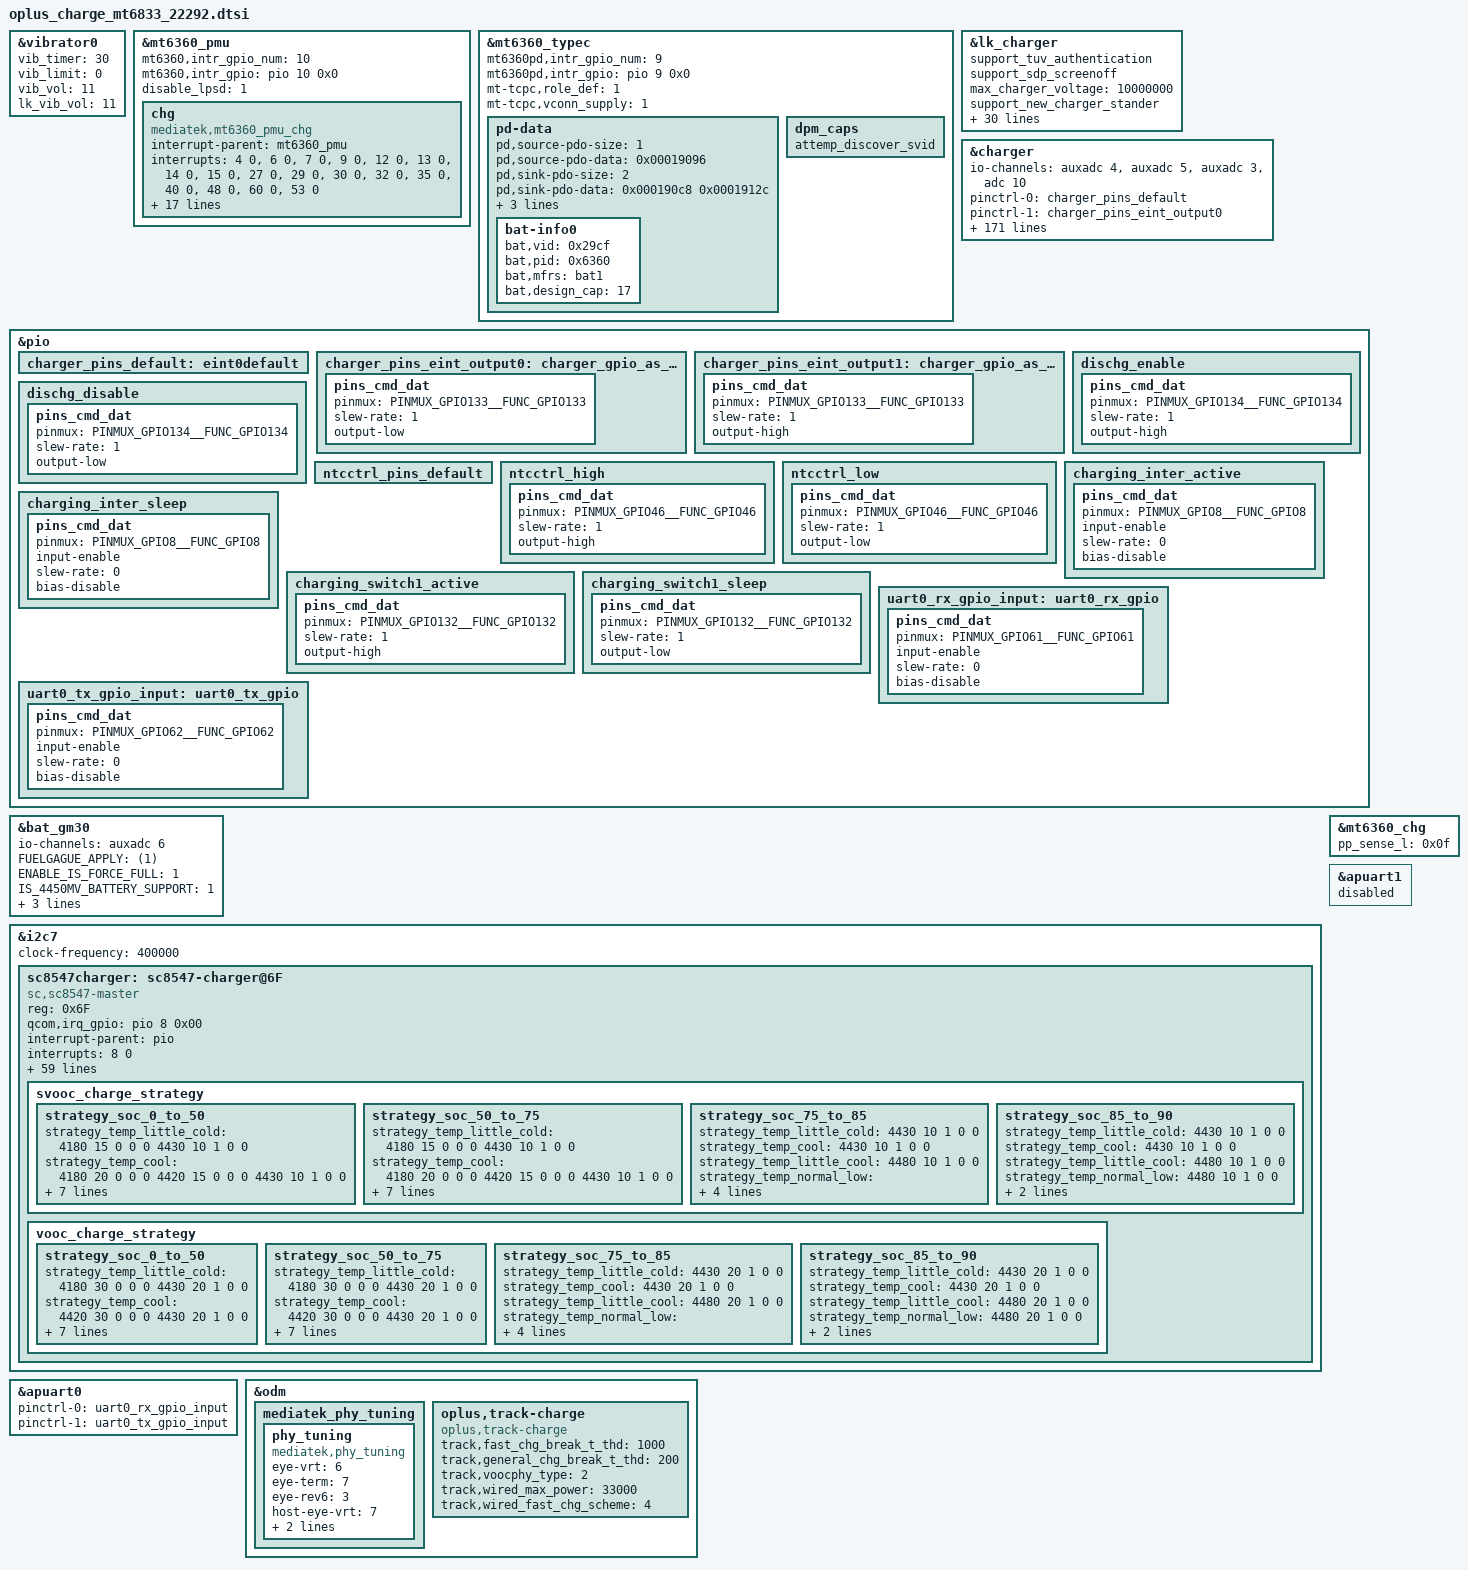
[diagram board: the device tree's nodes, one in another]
// SPDX-License-Identifier: GPL-2.0-only
/*
* Copyright (C) 2020-2021 Oplus. All rights reserved.
*/

//#ifdef OPLUS_FEATURE_CHG_BASIC
/*
 *
 * CPU:				--> MT6877
 * GPIO:
 * PERIEN_CHG_ENB		--> GPIO142
 * MT6360_SCL			--> GPIO132(SCL5)
 * MT6360_SDA			--> GPIO133(SDA5)
 * EINT_SUBPMIC_IRQB		--> GPIO4
 * EINT_SUBPMIC_PD_IRQB		--> GPIO5
 *
 * GAUGE_SCL			--> GPIO134(SCL7)
 * GAUGE_SDA			--> GPIO135(SDA7)
 * AP_CLK			--> GPIO180
 * AP_DATA			--> GPIO181
 * SW_CTRL			--> GPIO24
 * USB_ON			--> GPIO25
 * MCU_EN			--> GPIO33
 * ASIC_ID			--> GPIO34
 * ASIC_INT			--> GPIO9
 * SHIP_MODE_ON			--> GPIO108
 * UTXD0			--> GPIO178
 * URXD0			--> GPIO179
 *
 * USB_ACC_INT			--> GPIO6
 * VBUS_SHORT			--> GPIO167(VIO28)
 *
 * CHG_INT			--> GPIO10
 * CP_ID			--> GPIO31
 *
 * AUXADC:
 * 0				--> AUX_IN0_NTC_AP
 * 1				--> AUX_IN1_NTC_PA1
 * 2				--> AUX_IN2_NTC_PA2
 * 3				--> CAM_FLASH_THER
 * 4				--> USB_TEM_ADC_1
 * 5				--> USB_TEM_ADC_2
 * 6				--> CHG_MOS_THERM
 * 7				--> BATCON_TEM_ADC_MCU
 * 8				--> USBCON_TEM_ADC_MCU
 *******************************************
 * main pmic:			--> MT6365
 * charge pmic:			--> MT6360
 * charge ic:			--> MT6360
 * CP:				--> SC8547
 * GAUGE:			--> MT6365
 * asic ic:
 * PD				--> SY6610
 * HZ				--> RT5125
 * PU				--> RK826
 */

&vibrator0 {
	vib_timer = <30>;
	vib_limit = <0>;
	vib_vol= <11>;
	lk_vib_vol  = <11>;
	status = "okay";
};

&mt6360_pmu {
	mt6360,intr_gpio_num = <10>; /* direct defined GPIO num */
	mt6360,intr_gpio = <&pio 10 0x0>;
	disable_lpsd = <1>;

	chg {
		compatible = "mediatek,mt6360_pmu_chg";
		interrupt-parent = <&mt6360_pmu>;
		interrupts = <4 0>, <6 0>, <7 0>, <9 0>,
				<12 0>, <13 0>, <14 0>, <15 0>,
				<27 0>, <29 0>, <30 0>, <32 0>,
				<35 0>, <40 0>, <48 0>, <60 0>,
				<53 0>;
		interrupt-names = "chg_treg_evt", "chg_mivr_evt",
				"pwr_rdy_evt", "chg_batsysuv_evt",
				"chg_vsysuv_evt", "chg_vsysov_evt",
				"chg_vbatov_evt", "chg_vbusov_evt",
				"chg_tmri", "chg_adpbadi",
				"chg_rvpi",  "chg_aiccmeasl",
				"wdtmri", "pumpx_donei",
				"attachi", "chrdet_ext_evt",
				"hvdcp_det";
		io-channels = <&adc 0>, <&adc 1>, <&adc 3>, <&adc 4>,
				<&adc 5>, <&adc 6>, <&adc 8>, <&adc 10>;
		io-channel-names = "USBID", "VBUSDIV5", "VSYS", "VBAT",
				"IBUS", "IBAT", "TEMP_JC", "TS";
		chg_name = "primary_chg";
		ichg = <2000000>;               /* uA */
		aicr = <500000>;                /* uA */
		mivr = <4400000>;               /* uV */
		cv = <4350000>;                 /* uA */
		ieoc = <150000>;                /* uA */
		safety_timer = <20>;            /* hour */
		ircmp_resistor = <25000>;       /* uohm */
		ircmp_vclamp = <32000>;         /* uV */
		en_te = <1>;
		en_wdt = <1>;
		aicc_once = <1>;
		post_aicc = <1>;
		batoc_notify = <0>;
		support_hvdcp;
	};
};

&mt6360_typec {
	mt6360pd,intr_gpio_num = <9>; /* direct defined GPIO num */
	mt6360pd,intr_gpio = <&pio 9 0x0>;
	mt-tcpc,role_def = <1>;  /* 0: Unknown, 1: SNK only, 2: SRC only, 3: DRP, 4: Try.SRC, 5: Try.SNK */
	mt-tcpc,vconn_supply  = <1>; /* 0: Never, 1: Always, 2: EMarkOnly, 3: StartOnly */
	pd-data {
		pd,source-pdo-size = <1>;
		pd,source-pdo-data = <0x00019096>; /* Fixed5V1.5A */

		pd,sink-pdo-size = <2>;
		pd,sink-pdo-data = <0x000190c8 0x0001912c>; /* Fixed5V2A Fixed5V3A */

		pd,id-vdo-size = <3>;
		pd,id-vdo-data = <0xd10029cf 0x0 0x63600000>; /* No DP, host + device */

		bat,nr = <1>;
		bat-info0 {
			bat,vid = <0x29cf>;
			bat,pid = <0x6360>;
			bat,mfrs = "bat1";
			bat,design_cap = <17>; /*3.87V*4390mAh=16.98Wh*/
		};
	};

	dpm_caps {
		attemp_discover_svid;
	};
};

&lk_charger{
	support_tuv_authentication;
	support_sdp_screenoff;
	max_charger_voltage = <10000000>;

	support_new_charger_stander;
	usb_charger_current = <500000>;
	ac_charger_input_current = <2000000>;
	non_std_ac_charger_current = <2000000>;
	charging_host_charger_current = <1500000>;
	precharge_1_step_current = <350>;

	cold_bat_decidegc = <10>;  /*-10C~0C*/
	dcp_temp_cold_fastchg_current = <300>;
	usb_temp_cold_fastchg_current = <300>;
	cdp_temp_cold_fastchg_current = <300>;

	little_cold_bat_decidegc = <0>;    /*0C~5C*/
	dcp_temp_little_cold_fastchg_current = <700>;
	usb_temp_little_cold_fastchg_current = <500>;
	cdp_temp_little_cold_fastchg_current = <700>;

	cool_bat_decidegc = <5>;  /*5C~12C*/
	dcp_temp_cool_fastchg_current = <1600>;
	usb_temp_cool_fastchg_current = <600>;
	cdp_temp_cool_fastchg_current = <1600>;

	little_cool_bat_decidegc = <12>;  /*12C~16C*/
	dcp_temp_little_cool_fastchg_current = <2200>;
	usb_temp_little_cool_fastchg_current = <600>;
	cdp_temp_little_cool_fastchg_current = <1600>;

	normal_bat_decidegc = <16>;       /*16C~45C*/
	dcp_temp_normal_fastchg_current = <2200>;
	usb_temp_normal_fastchg_current = <600>;
	cdp_temp_normal_fastchg_current = <1600>;

	warm_bat_decidegc = <45>;    /*45C~53C*/
	dcp_temp_warm_fastchg_current = <2200>;
	usb_temp_warm_fastchg_current = <600>;
	cdp_temp_warm_fastchg_current = <1600>;

	hot_bat_decidegc = <53>;
};

&charger {
	io-channels = <&auxadc 4>,
		<&auxadc 5>,
		<&auxadc 3>,
		<&adc 10>;
	io-channel-names = "auxadc4-usb_temp_v_l",
		"auxadc5-usb_temp_v_r",
		"auxadc3-chargeric_temp",
		"auxadc10-batcon_temp";

	pinctrl-names = "default", "charger_gpio_as_output_low", "charger_gpio_as_output_high",
		"dischg_enable", "dischg_disable", "ntcctrl_pins_default", "ntcctrl_high", "ntcctrl_low";
	pinctrl-0 = <&charger_pins_default>;
	pinctrl-1 = <&charger_pins_eint_output0>;
	pinctrl-2 = <&charger_pins_eint_output1>;
	pinctrl-3 = <&dischg_enable>;
	pinctrl-4 = <&dischg_disable>;
	pinctrl-5 = <&ntcctrl_pins_default>;
	pinctrl-6 = <&ntcctrl_high>;
	pinctrl-7 = <&ntcctrl_low>;

	qcom,input_current_charger_ma = <2000>;
	qcom,pd_input_current_charger_ma = <2000>;
	qcom,qc_input_current_charger_ma = <2000>;
	qcom,input_current_usb_ma = <500>;
	qcom,input_current_cdp_ma = <1500>;
	qcom,input_current_camera_ma = <1200>;
	qcom,input_current_calling_ma = <1500>;

	qcom,led_warm_bat_decidegc = <370>;
	qcom,led_high_bat_decidegc = <390>;
	qcom,input_current_led_ma = <1500>;
	qcom,input_current_led_ma_high = <1500>;
	qcom,input_current_led_ma_warm = <2000>;
	qcom,input_current_led_ma_normal = <2000>;

	qcom,vooc_temp_bat_normal_decidegc = <350>;
	qcom,vooc_temp_bat_warm_decidegc = <370>;
	qcom,vooc_temp_bat_hot_decidegc = <440>;
	qcom,input_current_vooc_led_ma_high = <1200>;
	qcom,input_current_vooc_led_ma_warm = <1800>;
	qcom,input_current_vooc_led_ma_normal = <3600>;
	qcom,input_current_vooc_ma_normal = <3600>;

	qcom,input_current_vooc_ma_warm = <3200>;

	qcom,input_current_vooc_ma_high = <2200>;

	qcom,charger_current_vooc_ma_normal = <1800>;

	qcom,iterm_disabled = <0>;
	qcom,iterm_ma = <254>;
	qcom,recharge-mv = <100>;
	qcom,batt_capacity_mah = <5000>;/*typical capacity*/

	qcom,removed_bat_decidegc = <190>;  /*<-19C*/

	qcom,cold_bat_decidegc = <100>;  /*-10C~0C*/
	qcom,temp_cold_vfloat_mv = <4435>;
	qcom,temp_cold_fastchg_current_ma = <600>;
	qcom,temp_cold_fastchg_current_ma_high = <800>;
	qcom,temp_cold_fastchg_current_ma_low = <600>;
	qcom,pd_temp_cold_fastchg_current_ma_high = <800>;
	qcom,pd_temp_cold_fastchg_current_ma_low = <600>;
	qcom,qc_temp_cold_fastchg_current_ma_high = <800>;
	qcom,qc_temp_cold_fastchg_current_ma_low = <600>;

	qcom,little_cold_bat_decidegc = <0>;    /*0C~5C*/
	qcom,temp_little_cold_vfloat_mv = <4435>;
	qcom,temp_little_cold_fastchg_current_ma_high = <2200>;
	qcom,temp_little_cold_fastchg_current_ma_low = <2000>;
	qcom,temp_little_cold_fastchg_current_ma = <2000>;
	qcom,pd_temp_little_cold_fastchg_current_ma_high = <3000>;
	qcom,pd_temp_little_cold_fastchg_current_ma_low = <2000>;
	qcom,qc_temp_little_cold_fastchg_current_ma_high = <3000>;
	qcom,qc_temp_little_cold_fastchg_current_ma_low = <2000>;

	qcom,cool_bat_decidegc = <50>;  /*5C~12C*/
	qcom,temp_cool_vfloat_mv = <4435>;
	qcom,temp_cool_fastchg_current_ma_high = <2200>;
	qcom,temp_cool_fastchg_current_ma_low = <2200>;
	qcom,pd_temp_cool_fastchg_current_ma_high = <3000>;
	qcom,pd_temp_cool_fastchg_current_ma_low = <3000>;
	qcom,qc_temp_cool_fastchg_current_ma_high = <3000>;
	qcom,qc_temp_cool_fastchg_current_ma_low = <3000>;

	qcom,little_cool_bat_decidegc = <120>;  /*12C~16C*/
	qcom,temp_little_cool_vfloat_mv = <4435>;
	qcom,temp_little_cool_fastchg_current_ma = <2200>;
	qcom,pd_temp_little_cool_fastchg_current_ma = <3000>;
	qcom,qc_temp_little_cool_fastchg_current_ma = <3000>;

	qcom,normal_bat_decidegc = <160>;       /*16C~45C*/
	qcom,temp_normal_vfloat_mv = <4435>;
	qcom,temp_normal_fastchg_current_ma = <2200>;
	qcom,pd_temp_normal_fastchg_current_ma = <3000>;
	qcom,qc_temp_normal_fastchg_current_ma = <3000>;

	qcom,warm_bat_decidegc = <450>;         /*45C~53C*/ /*8pin Bat Vooc project need add 3 degree C*/
	qcom,temp_warm_vfloat_mv = <4130>;
	qcom,temp_warm_fastchg_current_ma = <2200>;
	qcom,pd_temp_warm_fastchg_current_ma = <2200>;
	qcom,qc_temp_warm_fastchg_current_ma = <2200>;
	qcom,temp_warm_fastchg_current_ma_led_on = <1000>;

	qcom,hot_bat_decidegc = <530>;

	qcom,non_standard_vfloat_mv = <3980>;
	qcom,non_standard_fastchg_current_ma = <500>;

	qcom,short_c_bat_cv_mv = <4330>;
	qcom,short_c_bat_vfloat_mv = <3800>;
	qcom,short_c_bat_fastchg_current_ma = <512>;

	qcom,cold_vfloat_sw_limit = <4385>;
	qcom,little_cold_vfloat_sw_limit = <4385>;
	qcom,cool_vfloat_sw_limit = <4385>;
	qcom,little_cool_vfloat_sw_limit = <4385>;
	qcom,normal_vfloat_sw_limit = <4385>;
	qcom,warm_vfloat_sw_limit = <4080>;
	qcom,non_standard_vfloat_sw_limit = <3930>;
	qcom,short_c_bat_vfloat_sw_limit = <3750>;

	qcom,max_chg_time_sec = <64800>;
	qcom,charger_hv_thr = <10000>;
	qcom,charger_recv_thr = <9800>;
	qcom,charger_lv_thr = <3400>;
	qcom,vbatt_full_thr = <4435>;
	qcom,vbatt_hv_thr = <4600>;

	qcom,vfloat_step_mv = <8>;
	qcom,cold_vfloat_over_sw_limit = <4445>;
	qcom,little_cold_vfloat_over_sw_limit = <4445>;
	qcom,cool_vfloat_over_sw_limit = <4445>;
	qcom,little_cool_vfloat_over_sw_limit = <4445>;
	qcom,normal_vfloat_over_sw_limit = <4445>;
	qcom,warm_vfloat_over_sw_limit = <4140>;
	qcom,non_standard_vfloat_over_sw_limit = <3990>;

	qcom,vbatt_power_off = <3300>;
	qcom,vbatt_soc_1 = <3310>;
	qcom,vooc_project = <5>;
	qcom,vbatt_num = <1>;
	qcom,new_ui_warning_support;
	qcom,voocphy_support = <2>;
	qcom,chargerid_support;
	qcom,ffc_support;
	qcom,smart_charging_screenoff;
	qcom,vooc_show_ui_soc_decimal;
	qcom,ui_soc_decimal_speedmin = <20>;//2A
	qcom,check_batt_full_by_sw;
	qcom,chg_ctrl_by_lcd;

	qcom,support_ntc_01c_precision;
	qcom,sw_vfloat_over_protect_enable;

	qcom,normal_vterm_hw_inc = <18>;
	qcom,non_normal_vterm_hw_inc = <18>;
	qcom,usbtemp_batttemp_gap = <12>;

	qcom,ff1_normal_fastchg_ma = <1500>;
	qcom,ff1_warm_fastchg_ma = <1500>;

	qcom,ffc2_normal_fastchg_ma = <1300>;/*12C~35c*/
	qcom,ffc2_temp_warm_decidegc = <350>;
	qcom,ffc2_warm_fastchg_ma = <1400>;/*35C~40c*/
	qcom,ffc2_temp_high_decidegc = <400>;
	qcom,ffc2_temp_low_decidegc = <120>;

	qcom,ff1_exit_step_ma = <450>;
	qcom,ff1_warm_exit_step_ma = <350>;
	qcom,ffc2_exit_step_ma = <150>;
	qcom,ffc2_warm_exit_step_ma = <150>;

	qcom,ffc_normal_vfloat_sw_limit = <4475>;
	qcom,ffc_temp_normal_vfloat_mv = <4550>;
	qcom,ffc_normal_vfloat_over_sw_limit = <4550>;
	qcom,ffc_warm_vfloat_sw_limit = <4475>;

	qcom,ffc2_normal_vfloat_sw_limit = <4475>;
	qcom,ffc2_temp_normal_vfloat_mv = <4550>;
	qcom,ffc2_normal_vfloat_over_sw_limit = <4550>;
	qcom,ffc2_warm_vfloat_sw_limit = <4475>;

	qcom,default_iterm_ma = <254>;
	qcom,default_temp_normal_fastchg_current_ma = <2200>;
	qcom,default_normal_vfloat_sw_limit = <4385>;
	qcom,default_temp_normal_vfloat_mv = <4435>;
	qcom,default_normal_vfloat_over_sw_limit = <4445>;

	qcom,default_temp_little_cool_fastchg_current_ma = <2200>;
	qcom,default_little_cool_vfloat_sw_limit = <4385>;
	qcom,default_temp_little_cool_vfloat_mv = <4435>;
	qcom,default_little_cool_vfloat_over_sw_limit = <4445>;

	//for PD9V or QC9V
	qcom,vbatt_pdqc_to_5v_thr = <4500>;
	qcom,vbatt_pdqc_to_9v_thr = <4500>;

	//GPIO config:
	qcom,chargerid_switch-gpio = <&pio 133 0x00>;
	qcom,dischg-gpio = <&pio 134 0x00>;
	qcom,ntcctrl-gpio = <&pio 46 0x00>;

	qcom,vooc-max-input-volt-support = <10000>;     //10V
	qcom,vooc-max-input-current-support = <3000>;   //3A
	qcom,disable-ship-mode;
};

&pio {
	charger_pins_default: eint0default {
	};

	charger_pins_eint_output0: charger_gpio_as_output_low {
		pins_cmd_dat {
			pinmux = <PINMUX_GPIO133__FUNC_GPIO133>;
			slew-rate = <1>;
			output-low;
		};
	};

	charger_pins_eint_output1: charger_gpio_as_output_high {
		pins_cmd_dat {
			pinmux = <PINMUX_GPIO133__FUNC_GPIO133>;
			slew-rate = <1>;
			output-high;
		};
	};

	dischg_enable: dischg_enable {
		pins_cmd_dat {
			pinmux = <PINMUX_GPIO134__FUNC_GPIO134>;
			slew-rate = <1>;
			output-high;
		};
	};

	dischg_disable: dischg_disable {
		pins_cmd_dat {
			pinmux = <PINMUX_GPIO134__FUNC_GPIO134>;
			slew-rate = <1>;
			output-low;
		};
	};

	ntcctrl_pins_default: ntcctrl_pins_default {
	};

	ntcctrl_high: ntcctrl_high {
		pins_cmd_dat {
			pinmux = <PINMUX_GPIO46__FUNC_GPIO46>;
			slew-rate = <1>;//0:input direction 1:output direction
			output-high;
		};
	};

	ntcctrl_low: ntcctrl_low {
		pins_cmd_dat {
			pinmux = <PINMUX_GPIO46__FUNC_GPIO46>;
			slew-rate = <1>;
			output-low;
		};
	};
};

&bat_gm30 {
	io-channels = <&auxadc 6>;
	io-channel-names = "auxadc6-batt_id_v";
	FUELGAGUE_APPLY = <(1)>;
	ENABLE_IS_FORCE_FULL = <1>;
	IS_4450MV_BATTERY_SUPPORT = <1>;
	KEEP_100_PERCENT = <(3)>;
	ACTIVE_TABLE = <(5)>;
	DIM2_TABLE_DISTINGUISH = <1>;
/*	USE_MT6360 = <1>;
	RBAT_TYPE = <(10)>;
	RBAT_PULL_UP_R = <(12000)>;
	FG_METER_RESISTANCE = <(0)>;
	COM_FG_METER_RESISTANCE = <(0)>;
	NO_BAT_TEMP_COMPENSATE = <(0)>;
	R_FG_VALUE = <(5)>;
	COM_R_FG_VALUE = <(5)>;
	EMBEDDED_SEL = <(1)>;
	DIFFERENCE_FULLOCV_ITH = <(300)>;
	SHUTDOWN_1_TIME = <(60)>;
*/
	#include "mediatek/bat_setting/mt6833_battery_prop_dim2_ext_22083.dtsi"
	#include "mediatek/bat_setting/mt6833_battery_table_cos_atl_22083.dtsi"
};

&i2c7 {
	status = "okay";
	clock-frequency = <400000>;//400K
	sc8547charger: sc8547-charger@6F {
		status = "okay";
		compatible = "sc,sc8547-master";
		reg = <0x6F>;

		qcom,irq_gpio = <&pio 8 0x00>;
		interrupt-parent = <&pio>;
		interrupts = <8 0>;

		pinctrl-names = "switch1_act_switch2_act", "switch1_sleep_switch2_sleep",
				"charging_inter_active", "charging_inter_sleep";
		pinctrl-0 = <&charging_switch1_active>;
		pinctrl-1 = <&charging_switch1_sleep>;
		pinctrl-2 = <&charging_inter_active>;
		pinctrl-3 = <&charging_inter_sleep>;

		qcom,charging_switch1-gpio = <&pio 132 0x00>;

		qcom,voocphy_current_default = <30>;

		qcom,svooc_cool_down_current_limit = <100 20 20 24 30 34 40 44 50 54 60 100>;
		qcom,vooc_cool_down_current_limit = <60 20 20 24 30 34 40 44 50 54 60>;

		qcom,vooc_little_cold_full_voltage = <4430>;
		qcom,vooc_cool_full_voltage = <4430>;
		qcom,vooc_warm_full_voltage = <4130>;
		qcom,vooc_1time_full_voltage = <4480>;
		qcom,vooc_ntime_full_voltage = <4480>;
		qcom,low_curr_full_t1 = <120>;
		qcom,low_curr_full_t2 = <350>;
		qcom,low_curr_full_t3 = <430>;
		qcom,range1_low_curr_full = <1150 4480
						1050 4475
						950 4460
						850 4450
						750 4440>;
		qcom,range2_low_curr_full = <1250 4480
						1150 4475
						1050 4460
						950 4450
						850 4440>;

		qcom,vooc_multistep_initial_batt_temp = <1000>;
		qcom,vooc_little_cool_temp = <160>;
		qcom,vooc_cool_temp = <120>;
		qcom,vooc_little_cold_temp = <50>;
		qcom,vooc_normal_low_temp = <250>;
		qcom,vooc_strategy_normal_current = <100>;
		qcom,vooc_normal_to_little_cool_current = <100>;
		qcom,vooc_batt_over_high_temp = <510>;
		qcom,vooc-low-temp = <0>;
		qcom,vooc-high-temp = <500>;
		qcom,vooc-low-soc = <0>;
		qcom,vooc-high-soc = <90>;
		qcom,vooc-normal-high-temp = <430>;
		qcom,vooc-warm-allow-vol = <4000>;
		qcom,vooc-warm-allow-soc = <50>;

		qcom,vooc_strategy1_batt_high_temp0 = <385>;
		qcom,vooc_strategy1_batt_high_temp1 = <395>;
		qcom,vooc_strategy1_batt_high_temp2 = <420>;
		qcom,vooc_strategy1_batt_low_temp2 = <410>;
		qcom,vooc_strategy1_batt_low_temp1 = <385>;
		qcom,vooc_strategy1_batt_low_temp0 = <375>;

		qcom,vooc_strategy1_high_current0 = <60>;
		qcom,vooc_strategy1_high_current1 = <60>;
		qcom,vooc_strategy1_high_current2 = <40>;
		qcom,vooc_strategy1_low_current2 = <60>;
		qcom,vooc_strategy1_low_current1 = <60>;
		qcom,vooc_strategy1_low_current0 = <100>;

		qcom,voocphy_ibat_over_current = <7500>;
		qcom,voocphy_cp_max_ibus = <3500>;

		qcom,voocphy_freq_mincore = <968000>;
		qcom,voocphy_freq_midcore = <1418000>;
		qcom,voocphy_freq_maxcore = <1418000>;
		qcom,voocphy_current_change_timeout = <100>;

		svooc_batt_sys_curve = <0 0 1 1 1 1 0	// 3000mA
					0 0 0 0 0 0 1	// 3414mV
					0 0 1 0 1 0 0	// 2000mA
					1 1 1 0 0 1 0	// 4550mV
					0 0 0 1 0 1 0	// 1000mA
					1 1 1 0 0 1 0>;	// 4550mV

		vooc_batt_sys_curve =  <0 0 1 1 1 1 0	// 3000mA
					0 0 0 0 0 0 1	// 3414mV
					0 0 1 0 1 0 0	// 2000mA
					1 1 1 0 0 1 0	// 4550mV
					0 0 0 1 0 1 0	// 1000mA
					1 1 1 0 0 1 0>;	// 4550mV

		svooc_charge_strategy {
			strategy_soc_0_to_50 {
				strategy_temp_little_cold =	<4180 15 0 0 0
								 4430 10 1 0 0>;
				strategy_temp_cool =		<4180 20 0 0 0
								 4420 15 0 0 0
								 4430 10 1 0 0>;
				strategy_temp_little_cool = 	<4450 20 0 0 0
								 4470 15 0 0 0
								 4480 10 1 0 0>;
				strategy_temp_normal_low =	<4200 30 0 1200 0
								 4450 25 0 1200 0
								 4450 23 0 0 0
								 4450 20 0 0 0
								 4470 15 0 0 0
								 4480 10 1 0 0>;
				strategy_temp_normal_high =	<4200 30 0 1200 0
								 4450 25 0 1200 0
								 4450 23 0 0 0
								 4450 20 0 0 0
								 4470 15 0 0 0
								 4480 10 1 0 0>;
				strategy_temp_warm =		<4130 10 1 0 0>;
			};

			strategy_soc_50_to_75 {
				strategy_temp_little_cold =	<4180 15 0 0 0
								 4430 10 1 0 0>;
				strategy_temp_cool =		<4180 20 0 0 0
								 4420 15 0 0 0
								 4430 10 1 0 0>;
				strategy_temp_little_cool =	<4450 20 0 0 0
								 4470 15 0 0 0
								 4480 10 1 0 0>;
				strategy_temp_normal_low =	<4450 25 0 1200 0
								 4450 23 0 0 0
								 4450 20 0 0 0
								 4470 15 0 0 0
								 4480 10 1 0 0>;
				strategy_temp_normal_high =	<4450 25 0 1200 0
								 4450 23 0 0 0
								 4450 20 0 0 0
								 4470 15 0 0 0
								 4480 10 1 0 0>;
				strategy_temp_warm =		<4130 10 1 0 0>;
			};

			strategy_soc_75_to_85 {
				strategy_temp_little_cold = 	<4430 10 1 0 0>;
				strategy_temp_cool =		<4430 10 1 0 0>;
				strategy_temp_little_cool =	<4480 10 1 0 0>;
				strategy_temp_normal_low =	<4470 15 0 0 0
								 4480 10 1 0 0>;
				strategy_temp_normal_high =	<4470 15 0 0 0
								 4480 10 1 0 0>;
				strategy_temp_warm =		<4130 10 1 0 0>;
			};

			strategy_soc_85_to_90 {
				strategy_temp_little_cold = 	<4430 10 1 0 0>;
				strategy_temp_cool =		<4430 10 1 0 0>;
				strategy_temp_little_cool =	<4480 10 1 0 0>;
				strategy_temp_normal_low =	<4480 10 1 0 0>;
				strategy_temp_normal_high =	<4480 10 1 0 0>;
				strategy_temp_warm =		<4130 10 1 0 0>;
			};
		};

		vooc_charge_strategy {
			strategy_soc_0_to_50 {
				strategy_temp_little_cold =	<4180 30 0 0 0
								 4430 20 1 0 0>;
				strategy_temp_cool =		<4420 30 0 0 0
								 4430 20 1 0 0>;
				strategy_temp_little_cool =	<4470 30 0 0 0
								 4480 20 1 0 0>;
				strategy_temp_normal_low =	<4470 30 0 0 0
								 4480 20 1 0 0>;
				strategy_temp_normal_high =	<4470 30 0 0 0
								 4480 20 1 0 0>;
				strategy_temp_warm =		<4130 20 1 0 0>;
			};

			strategy_soc_50_to_75 {
				strategy_temp_little_cold =	<4180 30 0 0 0
								 4430 20 1 0 0>;
				strategy_temp_cool =		<4420 30 0 0 0
								 4430 20 1 0 0>;
				strategy_temp_little_cool =	<4470 30 0 0 0
								 4480 20 1 0 0>;
				strategy_temp_normal_low =	<4450 40 0 0 0
								 4470 30 0 0 0
								 4480 20 1 0 0>;
				strategy_temp_normal_high =	<4450 40 0 0 0
								 4470 30 0 0 0
								 4480 20 1 0 0>;
				strategy_temp_warm =		<4130 20 1 0 0>;
			};

			strategy_soc_75_to_85 {
				strategy_temp_little_cold =	<4430 20 1 0 0>;
				strategy_temp_cool =		<4430 20 1 0 0>;
				strategy_temp_little_cool =	<4480 20 1 0 0>;
				strategy_temp_normal_low =	<4470 30 0 0 0
								 4480 20 1 0 0>;
				strategy_temp_normal_high =	<4470 30 0 0 0
								 4480 20 1 0 0>;
				strategy_temp_warm =		<4130 20 1 0 0>;
			};

			strategy_soc_85_to_90 {
				strategy_temp_little_cold =	<4430 20 1 0 0>;
				strategy_temp_cool =		<4430 20 1 0 0>;
				strategy_temp_little_cool =	<4480 20 1 0 0>;
				strategy_temp_normal_low =	<4480 20 1 0 0>;
				strategy_temp_normal_high =	<4480 20 1 0 0>;
				strategy_temp_warm =		<4130 20 1 0 0>;
			};
		};
	};
};

&mt6360_chg {
	pp_sense_l = <0x0f>;
};

&pio {
	charging_inter_active: charging_inter_active {
		pins_cmd_dat {
			pinmux = <PINMUX_GPIO8__FUNC_GPIO8>;
			input-enable;
			slew-rate = <0>;
			bias-disable;
		};
	};

	charging_inter_sleep: charging_inter_sleep {
		pins_cmd_dat {
			pinmux = <PINMUX_GPIO8__FUNC_GPIO8>;
			input-enable;
			slew-rate = <0>;
			bias-disable;
		};
	};

	charging_switch1_active: charging_switch1_active {
		pins_cmd_dat {
			pinmux = <PINMUX_GPIO132__FUNC_GPIO132>;
			slew-rate = <1>;
			output-high;
		};
	};

	charging_switch1_sleep: charging_switch1_sleep {
		pins_cmd_dat {
			pinmux = <PINMUX_GPIO132__FUNC_GPIO132>;
			slew-rate = <1>;
			output-low;
		};
	};
};

&apuart0 {
	pinctrl-names = "uart0_rx_gpio",
			"uart0_tx_gpio";
	pinctrl-0 = <&uart0_rx_gpio_input>;
	pinctrl-1 = <&uart0_tx_gpio_input>;
	status = "okay";
};

&apuart1 {
	status = "disabled";
};

&pio {
	uart0_rx_gpio_input:uart0_rx_gpio {
		pins_cmd_dat {
			pinmux = <PINMUX_GPIO61__FUNC_GPIO61>;
			input-enable;
			slew-rate = <0>;
			bias-disable;
		};
	};

	uart0_tx_gpio_input:uart0_tx_gpio {
		pins_cmd_dat {
			pinmux = <PINMUX_GPIO62__FUNC_GPIO62>;
			input-enable;
			slew-rate = <0>;
			bias-disable;
		};
	};
};

&odm {
	mediatek_phy_tuning: mediatek_phy_tuning {
		phy_tuning {
			compatible = "mediatek,phy_tuning";
			eye-vrt = <6>;
			eye-term = <7>;
			eye-rev6 = <3>;
			host-eye-vrt = <7>;
			host-eye-term = <5>;
			host-eye-rev6 = <3>;
		};
	};
	oplus,track-charge {
		compatible = "oplus,track-charge";
		track,fast_chg_break_t_thd = <1000>;
		track,general_chg_break_t_thd = <200>;
		track,voocphy_type = <2>;
		track,wired_max_power = <33000>;
		track,wired_fast_chg_scheme = <4>;
	};
};
//#endif /*OPLUS_FEATURE_CHG_BASIC*/
